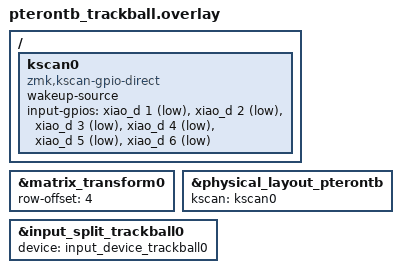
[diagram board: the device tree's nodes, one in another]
#include "pterontb.dtsi"

/ {
    kscan0: kscan0 {
        compatible = "zmk,kscan-gpio-direct";
        wakeup-source;

        input-gpios
            = <&xiao_d 1 (GPIO_ACTIVE_LOW | GPIO_PULL_UP)>
            , <&xiao_d 2 (GPIO_ACTIVE_LOW | GPIO_PULL_UP)>
            , <&xiao_d 3 (GPIO_ACTIVE_LOW | GPIO_PULL_UP)>
            , <&xiao_d 4 (GPIO_ACTIVE_LOW | GPIO_PULL_UP)>
            , <&xiao_d 5 (GPIO_ACTIVE_LOW | GPIO_PULL_UP)>
            , <&xiao_d 6 (GPIO_ACTIVE_LOW | GPIO_PULL_UP)>
            ;
    };
};

&matrix_transform0 {
    row-offset = <4>;
};

&physical_layout_pterontb {
    kscan = <&kscan0>;
};
// == Input devices ==
// Enabling input-split for its own input devices
// Adding input devices and assigning them to input-split
&input_split_trackball0 {
    status = "okay";
    device = <&input_device_trackball0>;
};

